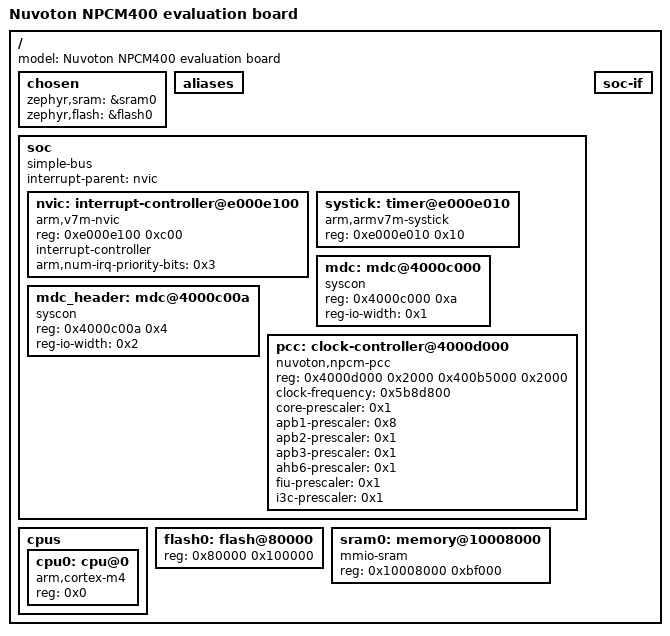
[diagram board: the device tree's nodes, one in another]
/dts-v1/;

/* node '/' defined in zephyr/dts/common/skeleton.dtsi:9 */
/ {
	#address-cells = < 0x1 >;                   /* in zephyr/dts/common/skeleton.dtsi:10 */
	#size-cells = < 0x1 >;                      /* in zephyr/dts/common/skeleton.dtsi:11 */
	model = "Nuvoton NPCM400 evaluation board"; /* in zephyr/boards/nuvoton/npcm400_evb/npcm400_evb.dts:12 */

	/* node '/chosen' defined in zephyr/dts/common/skeleton.dtsi:13 */
	chosen {
		zephyr,sram = &sram0;   /* in zephyr/boards/nuvoton/npcm400_evb/npcm400_evb.dts:15 */
		zephyr,flash = &flash0; /* in zephyr/boards/nuvoton/npcm400_evb/npcm400_evb.dts:16 */
	};

	/* node '/aliases' defined in zephyr/dts/common/skeleton.dtsi:15 */
	aliases {
	};

	/* node '/soc' defined in zephyr/dts/arm/armv7-m.dtsi:6 */
	soc {
		#address-cells = < 0x1 >;     /* in zephyr/dts/arm/armv7-m.dtsi:7 */
		#size-cells = < 0x1 >;        /* in zephyr/dts/arm/armv7-m.dtsi:8 */
		compatible = "simple-bus";    /* in zephyr/dts/arm/armv7-m.dtsi:9 */
		interrupt-parent = < &nvic >; /* in zephyr/dts/arm/armv7-m.dtsi:10 */
		ranges;                       /* in zephyr/dts/arm/armv7-m.dtsi:11 */

		/* node '/soc/interrupt-controller@e000e100' defined in zephyr/dts/arm/armv7-m.dtsi:13 */
		nvic: interrupt-controller@e000e100 {
			#address-cells = < 0x1 >;            /* in zephyr/dts/arm/armv7-m.dtsi:14 */
			compatible = "arm,v7m-nvic";         /* in zephyr/dts/arm/armv7-m.dtsi:15 */
			reg = < 0xe000e100 0xc00 >;          /* in zephyr/dts/arm/armv7-m.dtsi:16 */
			interrupt-controller;                /* in zephyr/dts/arm/armv7-m.dtsi:17 */
			#interrupt-cells = < 0x2 >;          /* in zephyr/dts/arm/armv7-m.dtsi:18 */
			arm,num-irq-priority-bits = < 0x3 >; /* in zephyr/dts/arm/nuvoton/npcm/npcm.dtsi:52 */
			phandle = < 0x1 >;                   /* in zephyr/dts/arm/armv7-m.dtsi:10 */
		};

		/* node '/soc/timer@e000e010' defined in zephyr/dts/arm/armv7-m.dtsi:21 */
		systick: timer@e000e010 {
			compatible = "arm,armv7m-systick"; /* in zephyr/dts/arm/armv7-m.dtsi:22 */
			reg = < 0xe000e010 0x10 >;         /* in zephyr/dts/arm/armv7-m.dtsi:23 */
		};

		/* node '/soc/mdc@4000c000' defined in zephyr/dts/arm/nuvoton/npcm/npcm.dtsi:26 */
		mdc: mdc@4000c000 {
			compatible = "syscon";    /* in zephyr/dts/arm/nuvoton/npcm/npcm4.dtsi:14 */
			reg = < 0x4000c000 0xa >; /* in zephyr/dts/arm/nuvoton/npcm/npcm4.dtsi:15 */
			reg-io-width = < 0x1 >;   /* in zephyr/dts/arm/nuvoton/npcm/npcm4.dtsi:16 */
		};

		/* node '/soc/mdc@4000c00a' defined in zephyr/dts/arm/nuvoton/npcm/npcm.dtsi:32 */
		mdc_header: mdc@4000c00a {
			compatible = "syscon";    /* in zephyr/dts/arm/nuvoton/npcm/npcm4.dtsi:20 */
			reg = < 0x4000c00a 0x4 >; /* in zephyr/dts/arm/nuvoton/npcm/npcm4.dtsi:21 */
			reg-io-width = < 0x2 >;   /* in zephyr/dts/arm/nuvoton/npcm/npcm4.dtsi:22 */
		};

		/* node '/soc/clock-controller@4000d000' defined in zephyr/dts/arm/nuvoton/npcm/npcm.dtsi:38 */
		pcc: clock-controller@4000d000 {
			compatible = "nuvoton,npcm-pcc";               /* in zephyr/dts/arm/nuvoton/npcm/npcm.dtsi:39 */
			#clock-cells = < 0x1 >;                        /* in zephyr/dts/arm/nuvoton/npcm/npcm.dtsi:41 */
			reg = < 0x4000d000 0x2000 0x400b5000 0x2000 >; /* in zephyr/dts/arm/nuvoton/npcm/npcm.dtsi:44 */
			reg-names = "pmc",
			            "cdcg";                            /* in zephyr/dts/arm/nuvoton/npcm/npcm.dtsi:46 */
			clock-frequency = < 0x5b8d800 >;               /* in zephyr/dts/arm/nuvoton/npcm/npcm4.dtsi:26 */
			core-prescaler = < 0x1 >;                      /* in zephyr/dts/arm/nuvoton/npcm/npcm4.dtsi:27 */
			apb1-prescaler = < 0x8 >;                      /* in zephyr/dts/arm/nuvoton/npcm/npcm4.dtsi:28 */
			apb2-prescaler = < 0x1 >;                      /* in zephyr/dts/arm/nuvoton/npcm/npcm4.dtsi:29 */
			apb3-prescaler = < 0x1 >;                      /* in zephyr/dts/arm/nuvoton/npcm/npcm4.dtsi:30 */
			ahb6-prescaler = < 0x1 >;                      /* in zephyr/dts/arm/nuvoton/npcm/npcm4.dtsi:31 */
			fiu-prescaler = < 0x1 >;                       /* in zephyr/dts/arm/nuvoton/npcm/npcm4.dtsi:32 */
			i3c-prescaler = < 0x1 >;                       /* in zephyr/dts/arm/nuvoton/npcm/npcm4.dtsi:33 */
		};
	};

	/* node '/cpus' defined in zephyr/dts/arm/nuvoton/npcm/npcm.dtsi:14 */
	cpus {
		#address-cells = < 0x1 >; /* in zephyr/dts/arm/nuvoton/npcm/npcm.dtsi:15 */
		#size-cells = < 0x0 >;    /* in zephyr/dts/arm/nuvoton/npcm/npcm.dtsi:16 */

		/* node '/cpus/cpu@0' defined in zephyr/dts/arm/nuvoton/npcm/npcm.dtsi:18 */
		cpu0: cpu@0 {
			device_type = "cpu";          /* in zephyr/dts/arm/nuvoton/npcm/npcm.dtsi:19 */
			compatible = "arm,cortex-m4"; /* in zephyr/dts/arm/nuvoton/npcm/npcm.dtsi:20 */
			reg = < 0x0 >;                /* in zephyr/dts/arm/nuvoton/npcm/npcm.dtsi:21 */
		};
	};

	/* node '/soc-if' defined in zephyr/dts/arm/nuvoton/npcm/npcm4.dtsi:37 */
	soc-if {
	};

	/* node '/flash@80000' defined in zephyr/dts/arm/nuvoton/npcm400.dtsi:12 */
	flash0: flash@80000 {
		reg = < 0x80000 0x100000 >; /* in zephyr/dts/arm/nuvoton/npcm400.dtsi:13 */
	};

	/* node '/memory@10008000' defined in zephyr/dts/arm/nuvoton/npcm400.dtsi:16 */
	sram0: memory@10008000 {
		compatible = "mmio-sram";     /* in zephyr/dts/arm/nuvoton/npcm400.dtsi:17 */
		reg = < 0x10008000 0xbf000 >; /* in zephyr/dts/arm/nuvoton/npcm400.dtsi:18 */
	};
};
